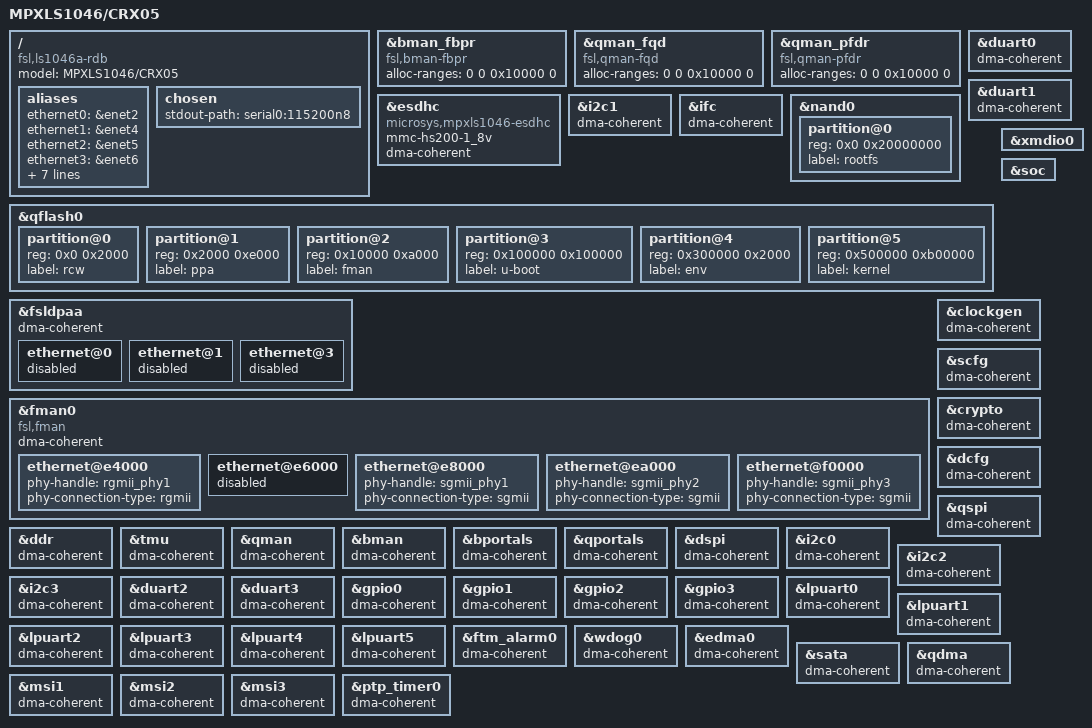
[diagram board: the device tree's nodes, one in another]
/*
 * Device Tree Include file for Freescale Layerscape-1046A family SoC.
 *
 * Copyright 2019 NXP
 * Copyright (C) 2019 MicroSys Electronics GmbH
 *
 * Mingkai Hu <mingkai.hu@nxp.com>
 *
 * This file is dual-licensed: you can use it either under the terms
 * of the GPLv2 or the X11 license, at your option. Note that this dual
 * licensing only applies to this file, and not this project as a
 * whole.
 *
 *  a) This library is free software; you can redistribute it and/or
 *     modify it under the terms of the GNU General Public License as
 *     published by the Free Software Foundation; either version 2 of the
 *     License, or (at your option) any later version.
 *
 *     This library is distributed in the hope that it will be useful,
 *     but WITHOUT ANY WARRANTY; without even the implied warranty of
 *     MERCHANTABILITY or FITNESS FOR A PARTICULAR PURPOSE.  See the
 *     GNU General Public License for more details.
 *
 * Or, alternatively,
 *
 *  b) Permission is hereby granted, free of charge, to any person
 *     obtaining a copy of this software and associated documentation
 *     files (the "Software"), to deal in the Software without
 *     restriction, including without limitation the rights to use,
 *     copy, modify, merge, publish, distribute, sublicense, and/or
 *     sell copies of the Software, and to permit persons to whom the
 *     Software is furnished to do so, subject to the following
 *     conditions:
 *
 *     The above copyright notice and this permission notice shall be
 *     included in all copies or substantial portions of the Software.
 *
 *     THE SOFTWARE IS PROVIDED "AS IS", WITHOUT WARRANTY OF ANY KIND,
 *     EXPRESS OR IMPLIED, INCLUDING BUT NOT LIMITED TO THE WARRANTIES
 *     OF MERCHANTABILITY, FITNESS FOR A PARTICULAR PURPOSE AND
 *     NONINFRINGEMENT. IN NO EVENT SHALL THE AUTHORS OR COPYRIGHT
 *     HOLDERS BE LIABLE FOR ANY CLAIM, DAMAGES OR OTHER LIABILITY,
 *     WHETHER IN AN ACTION OF CONTRACT, TORT OR OTHERWISE, ARISING
 *     FROM, OUT OF OR IN CONNECTION WITH THE SOFTWARE OR THE USE OR
 *     OTHER DEALINGS IN THE SOFTWARE.
 */

/dts-v1/;

#include "fsl-ls1046a.dtsi"
#include "qoriq-qman-portals-sdk.dtsi"
#include "qoriq-bman-portals-sdk.dtsi"

/ {
	model = "MPXLS1046/CRX05";
	compatible = "fsl,ls1046a-rdb", "fsl,ls1046a";

	aliases {
		ethernet0 = &enet2; /* fm1mac3 */
		ethernet1 = &enet4; /* fm1mac5 */
		ethernet2 = &enet5; /* fm1mac6 */
		ethernet3 = &enet6; /* fm1mac9 */

		serial0 = &duart0;
		serial1 = &duart1;
		serial2 = &duart2;
		serial3 = &duart3;

		mdio0 = &mdio0;
		mdio1 = &xmdio0;

		crypto = &crypto;
	};

	chosen {
		stdout-path = "serial0:115200n8";
	};
};

&bman_fbpr {
	compatible = "fsl,bman-fbpr";
	alloc-ranges = <0 0 0x10000 0>;
};
&qman_fqd {
	compatible = "fsl,qman-fqd";
	alloc-ranges = <0 0 0x10000 0>;
};
&qman_pfdr {
	compatible = "fsl,qman-pfdr";
	alloc-ranges = <0 0 0x10000 0>;
};


&esdhc {
	compatible = "microsys,mpxls1046-esdhc", "fsl,ls1046a-esdhc", "fsl,esdhc";
	mmc-hs200-1_8v;
};

&duart0 {
	status = "okay";
};

&duart1 {
	status = "okay";
};

&i2c1 {
	status = "okay";
};

#include "fsl-ls1046-post.dtsi"
#include "mpxls10xx_common.dtsi"
#include "mpxls10xx_crx05.dtsi"

&ifc {
	status = "okay";
	#address-cells = <2>;
	#size-cells = <1>;
	ranges = <0x0 0x0 0x0 0x7e800000 0x00010000>;
};

&nand0 {
		partition@0 {
			reg = <0x0 0x20000000>;
			label = "rootfs";
		};
};

&qflash0 {
		partition@0 {
			reg = <0x0 0x2000>;
			label = "rcw";
		};
		partition@1 {
			reg = <0x2000 0xe000>;
			label = "ppa";
		};
		partition@2 {
			reg = <0x10000 0xa000>;
			label = "fman";
		};
		partition@3 {
			reg = <0x100000 0x100000>;
			label = "u-boot";
		};
		partition@4 {
			reg = <0x300000 0x2000>;
			label = "env";
		};
		partition@5 {
			reg = <0x500000 0xb00000>;
			label = "kernel";
		};
};

&xmdio0 {
};

&soc {
#include "qoriq-dpaa-eth.dtsi"
#include "qoriq-fman3-0-6oh.dtsi"
};

&fsldpaa {

	ethernet@0 {
		status = "disabled";
	};

	ethernet@1 {
		status = "disabled";
	};

	ethernet@3 {
		status = "disabled";
	};

};

&fman0 {

	compatible = "fsl,fman", "simple-bus";

	ethernet@e4000 {
		phy-handle = <&rgmii_phy1>;
		phy-connection-type = "rgmii";
	};

	ethernet@e6000 {
		status = "disabled";
	};

	ethernet@e8000 {
		phy-handle = <&sgmii_phy1>;
		phy-connection-type = "sgmii";
	};

	ethernet@ea000 {
		phy-handle = <&sgmii_phy2>;
		phy-connection-type = "sgmii";
	};

	ethernet@f0000 {
		phy-handle = <&sgmii_phy3>;
		phy-connection-type = "sgmii";
	};
};
&clockgen {
	dma-coherent;
};

&scfg {
	dma-coherent;
};

&crypto {
	dma-coherent;
};

&dcfg {
	dma-coherent;
};

&ifc {
	dma-coherent;
};

&qspi {
	dma-coherent;
};

&esdhc {
	dma-coherent;
};

&ddr {
	dma-coherent;
};

&tmu {
	dma-coherent;
};

&qman {
	dma-coherent;
};

&bman {
	dma-coherent;
};

&bportals {
	dma-coherent;
};

&qportals {
	dma-coherent;
};

&dspi {
	dma-coherent;
};

&i2c0 {
	dma-coherent;
};

&i2c1 {
	dma-coherent;
};

&i2c2 {
	dma-coherent;
};

&i2c3 {
	dma-coherent;
};

&duart0 {
	dma-coherent;
};

&duart1 {
	dma-coherent;
};

&duart2 {
	dma-coherent;
};

&duart3 {
	dma-coherent;
};

&gpio0 {
	dma-coherent;
};

&gpio1 {
	dma-coherent;
};

&gpio2 {
	dma-coherent;
};

&gpio3 {
	dma-coherent;
};

&lpuart0 {
	dma-coherent;
};

&lpuart1 {
	dma-coherent;
};

&lpuart2 {
	dma-coherent;
};

&lpuart3 {
	dma-coherent;
};

&lpuart4 {
	dma-coherent;
};

&lpuart5 {
	dma-coherent;
};

&ftm_alarm0 {
	dma-coherent;
};

&wdog0 {
	dma-coherent;
};

&edma0 {
	dma-coherent;
};

&sata {
	dma-coherent;
};

&qdma {
	dma-coherent;
};

&msi1 {
	dma-coherent;
};

&msi2 {
	dma-coherent;
};

&msi3 {
	dma-coherent;
};

&fman0 {
	dma-coherent;
};

&ptp_timer0 {
	dma-coherent;
};

&fsldpaa {
	dma-coherent;
};
